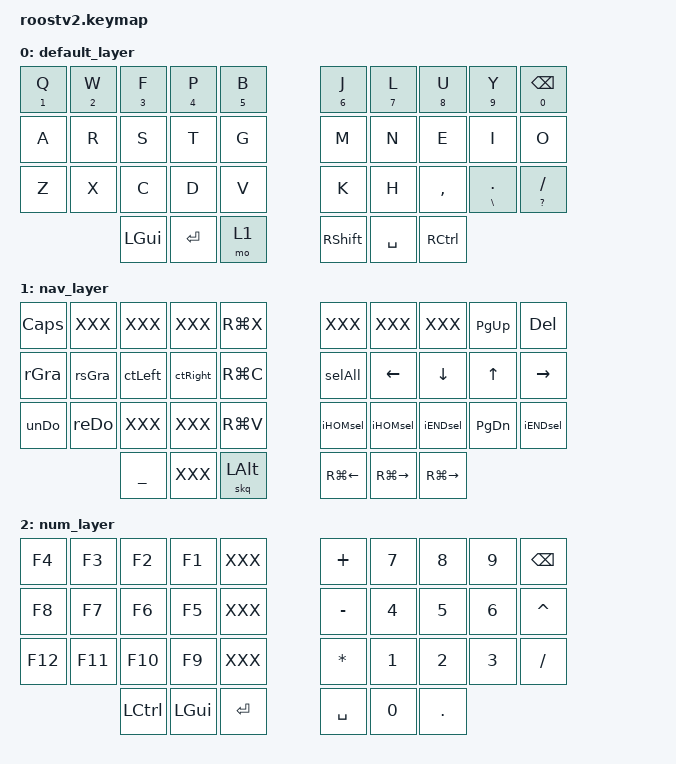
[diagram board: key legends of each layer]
#include <behaviors.dtsi>
#include <dt-bindings/zmk/keys.h>
#include <dt-bindings/zmk/bt.h>
#include "roostv2.h"

&mt {
    tapping-term-ms = <300>;
};

/ { 
    behaviors {
        hm: hold_mods {
            compatible = "zmk,behavior-hold-tap";
            label = "HOLD_TAP";
            #binding-cells = <2>;
            tapping-term-ms = <180>;
            quick_tap_ms = <0>;
            flavor = "balanced";
            bindings = <&kp>, <&kp>;
        };
        skq: sticky_key_quick_release {
            compatible = "zmk,behavior-sticky-key";
            label = "STICKY_KEY_QUICK_RELEASE";
            #binding-cells = <1>;
            bindings = <&kp>;
            release-after-ms = <2000>;
            quick-release;
        };
        lst: layer_sticky_tap {
            compatible = "zmk,behavior-hold-tap";
            label = "LAYER_STICKY_TAP";
            #binding-cells = <2>;
            tapping-term-ms = <200>;
            quick_tap_ms = <0>;
            flavor = "tap-preferred";
            bindings = <&mo>, <&sk>;
        };
    };

    combos {
        #include "combos.dtsi"
    };

    keymap {
            compatible = "zmk,keymap";
            
    	default_layer {
    		bindings = <
            // ╭─────────────┬─────────────┬─────────────┬─────────────┬─────────────╮   ╭─────────────┬─────────────┬─────────────┬─────────────┬─────────────╮
                 &hm N1 Q      &hm N2 W      &hm N3 F      &hm N4 P      &hm N5 B          &hm N6 J      &hm N7 L      &hm N8 U      &hm N9 Y      &hm N0 BSPC 
            // ├─────────────┼─────────────┼─────────────┼─────────────┼─────────────┤   ├─────────────┼─────────────┼─────────────┼─────────────┼─────────────┤
                 &kp A         &kp R         &kp S         &kp T         &kp G             &kp M         &kp N         &kp E         &kp I         &kp O
            // ├─────────────┼─────────────┼─────────────┼─────────────┼─────────────┤   ├─────────────┼─────────────┼─────────────┼─────────────┼─────────────┤
                 &kp Z         &kp X         &kp C         &kp D         &kp V	           &kp K         &kp H         &kp COMMA     &hm BSLH DOT  &hm QMARK SLASH
            // ╰─────────────┴─────────────┼─────────────┼─────────────┼─────────────┤   ├─────────────┼─────────────┼─────────────┼─────────────┴─────────────╯
                                             &kp LGUI      &kp RET       &mo 1             &kp RSHFT     &kp SPACE     &kp RCTRL
            //                             ╰─────────────┴─────────────┴─────────────╯   ╰─────────────┴─────────────┴─────────────╯
		    >;
      };
		  
      nav_layer {
          bindings = <
          // ╭─────────────┬─────────────┬─────────────┬─────────────┬─────────────╮   ╭─────────────┬─────────────┬─────────────┬─────────────┬─────────────╮
               &kp CAPS      &kp XXX       &kp XXX       &kp XXX       &kp RG(X)         &kp XXX       &kp XXX       &kp XXX       &kp PG_UP     &kp DEL
          // ├─────────────┼─────────────┼─────────────┼─────────────┼─────────────┤   ├─────────────┼─────────────┼─────────────┼─────────────┼─────────────┤
               &kp rGra      &kp rsGra     &kp ctLeft    &kp ctRight   &kp RG(C)         &kp selAll    &kp LEFT      &kp DOWN      &kp UP        &kp RIGHT
          // ├─────────────┼─────────────┼─────────────┼─────────────┼─────────────┤   ├─────────────┼─────────────┼─────────────┼─────────────┼─────────────┤
               &kp unDo      &kp reDo      &kp XXX       &kp XXX       &kp RG(V)         &kp iHOMsel   &kp iHOMsel   &kp iENDsel   &kp PG_DN     &kp iENDsel
          // ╰─────────────┴─────────────┼─────────────┼─────────────┼─────────────┤   ├─────────────┼─────────────┼─────────────┼─────────────┴─────────────╯
                                           ___           &kp XXX       &skq LALT         &kp RG(LEFT)  &kp RG(RIGHT) &kp RG(RIGHT)
          //                             ╰─────────────┴─────────────┴─────────────╯   ╰─────────────┴─────────────┴─────────────╯
          >;
      };
      
      num_layer {
          bindings = <
          // ╭─────────────┬─────────────┬─────────────┬─────────────┬─────────────╮   ╭─────────────┬─────────────┬─────────────┬─────────────┬─────────────╮
               &kp F4        &kp F3        &kp F2        &kp F1        &kp XXX           &kp PLUS      &kp N7        &kp N8        &kp N9        &kp BSPC
          // ├─────────────┼─────────────┼─────────────┼─────────────┼─────────────┤   ├─────────────┼─────────────┼─────────────┼─────────────┼─────────────┤
               &kp F8        &kp F7        &kp F6        &kp F5        &kp XXX           &kp MINUS     &kp N4        &kp N5        &kp N6        &kp CARET 
          // ├─────────────┼─────────────┼─────────────┼─────────────┼─────────────┤   ├─────────────┼─────────────┼─────────────┼─────────────┼─────────────┤
               &kp F12       &kp F11       &kp F10       &kp F9        &kp XXX           &kp STAR      &kp N1        &kp N2        &kp N3        &kp SLASH 
          // ╰─────────────┴─────────────┼─────────────┼─────────────┼─────────────┤   ├─────────────┼─────────────┼─────────────┼─────────────┴─────────────╯
                                           &kp LCTRL     &kp LGUI      &kp RET           &kp SPACE     &kp N0        &kp DOT 
          //                             ╰─────────────┴─────────────┴─────────────╯   ╰─────────────┴─────────────┴─────────────╯
          >;
      };   
    };
};
